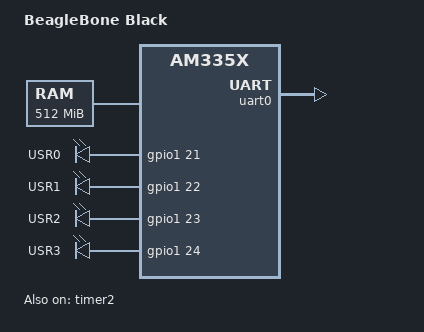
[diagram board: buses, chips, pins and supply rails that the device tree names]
/* SPDX-License-Identifier: Apache-2.0 */

/dts-v1/;

#include <ti/am335x.dtsi>

/ {
	model = "BeagleBone Black";
	compatible = "ti,am335x-bone-black", "ti,am335x";

	chosen {
		zephyr,console = &uart0;
		zephyr,shell-uart = &uart0;
		zephyr,ram = &memory0;
		zephyr,code-partition = &memory0;
	};


    memory0: memory@80000000 {
        device_type = "memory";
        reg = <0x80000000 0x20000000>; /* 512 MB */
    };


	leds {
		compatible = "gpio-leds";
		
		led0: led_0 {
			gpios = <&gpio1 21 GPIO_ACTIVE_HIGH>;
			label = "USR0";
		};

		led1: led_1 {
			gpios = <&gpio1 22 GPIO_ACTIVE_HIGH>;
			label = "USR1";
		};

		led2: led_2 {
			gpios = <&gpio1 23 GPIO_ACTIVE_HIGH>;
			label = "USR2";
		};

		led3: led_3 {
			gpios = <&gpio1 24 GPIO_ACTIVE_HIGH>;
			label = "USR3";
		};
	};

	aliases {
		led0 = &led0;
		led1 = &led1;
		led2 = &led2;
		led3 = &led3;
	};
};

/* Pinctrl configuration */
&pinctrl {
	uart0_pins: uart0_pins {
		pinmux = <
			AM335X_PINMUX(AM335X_PIN_UART0_RXD, 0, AM335X_PIN_INPUT_PULLUP)
			AM335X_PINMUX(AM335X_PIN_UART0_TXD, 0, AM335X_PIN_OUTPUT)
		>;
	};

	gpio_led_pins: gpio_led_pins {
		pinmux = <
			AM335X_PINMUX(AM335X_PIN_GPMC_A5, 7, AM335X_PIN_OUTPUT)
			AM335X_PINMUX(AM335X_PIN_GPMC_A6, 7, AM335X_PIN_OUTPUT)
			AM335X_PINMUX(AM335X_PIN_GPMC_A7, 7, AM335X_PIN_OUTPUT)
			AM335X_PINMUX(AM335X_PIN_GPMC_A8, 7, AM335X_PIN_OUTPUT)
		>;
	};
};

/* Enable and configure UART0 for console */
&uart0 {
	status = "okay";
	pinctrl-0 = <&uart0_pins>;
	pinctrl-names = "default";
};

/* Enable GPIO0 */
&gpio0 {
	status = "okay";
};

/* Enable GPIO1 for LEDs */
&gpio1 {
	status = "okay";
	pinctrl-0 = <&gpio_led_pins>;
	pinctrl-names = "default";
};

/* Enable Timer2 for system clock */
&timer2 {
	status = "okay";
};
